# MLB0_MLBDIM_WRAP_ECC_AGGR_VBP register map
Vendor: Texas Instruments
Peripheral module from a debugger description file (folder J7ES).
Registers are 32-bit, access not given, reset 0x0 unless marked. A register's access mark holds for its fields unless they carry their own. Offsets are as the file gives them; lines under a group give offsets from that group; [hi:lo] are bit positions; {n}, {i} and the like mark numbered series; 'fields as' and 'values as' point back to an identical list; <NAME> marks a mode.

## MLB0_MLBDIM_WRAP_ECC_AGGR_VBP
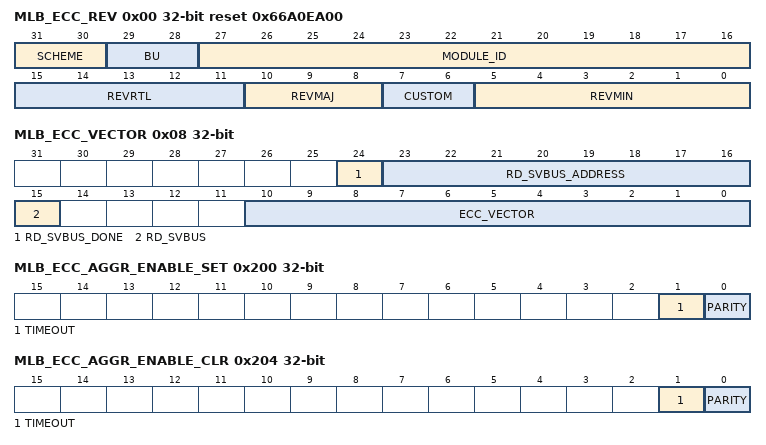
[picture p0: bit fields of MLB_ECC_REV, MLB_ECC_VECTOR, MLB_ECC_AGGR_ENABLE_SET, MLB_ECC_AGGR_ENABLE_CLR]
0x00 MLB_ECC_REV ro reset 0x66A0EA00 — Revision parameters
  [31:30] SCHEME
  [29:28] BU
  [27:16] MODULE_ID
  [15:11] REVRTL — RTL version
  [10:8] REVMAJ — Major version
  [7:6] CUSTOM — Custom version
  [5:0] REVMIN — Minor version
0x08 MLB_ECC_VECTOR — ECC Vector Register
  [24] RD_SVBUS_DONE — Status to indicate if read on serial VBUS is complete, write of any value will clear this bit. (access RW1C)
  [23:16] RD_SVBUS_ADDRESS rw — Read address
  [15] RD_SVBUS — Write 1 to trigger a read on the serial VBUS (access RW1S)
  [10:0] ECC_VECTOR rw — Value written to select the corresponding ECC RAM for control or status
0x0C MLB_ECC_STAT ro reset 0x1 — Misc Status
  [10:0] NUM_RAMS — Indicates the number of RAMS serviced by the ECC aggregator
0x10 MLB_ECC_RESERVED_SVBUS_y rw — Reference other documents that contain the ECC RAM wrapper and EDC controller serial vbus register sets. Offset = 10h + (y * 4h); where y = 0h to 7h
  [31:0] DATA — Serial VBUS register data
0x3C MLB_ECC_SEC_EOI_REG — EOI Register
  [0] EOI_WR — EOI Register (access RW1S)
0x40 MLB_ECC_SEC_STATUS_REG0 — Interrupt Status Register 0
  [0] DBMEM_PEND — Interrupt Pending Status for dbmem_pend (access RW1S)
0x80 MLB_ECC_SEC_ENABLE_SET_REG0 — Interrupt Enable Set Register 0
  [0] DBMEM_ENABLE_SET — Interrupt Enable Set Register for dbmem_pend (access RW1S)
0xC0 MLB_ECC_SEC_ENABLE_CLR_REG0 — Interrupt Enable Clear Register 0
  [0] DBMEM_ENABLE_CLR — Interrupt Enable Clear Register for dbmem_pend (access RW1C)
0x13C MLB_ECC_DED_EOI_REG — EOI Register
  [0] EOI_WR — EOI Register (access RW1S)
0x140 MLB_ECC_DED_STATUS_REG0 — Interrupt Status Register 0
  fields as MLB_ECC_SEC_STATUS_REG0
0x180 MLB_ECC_DED_ENABLE_SET_REG0 — Interrupt Enable Set Register 0
  fields as MLB_ECC_SEC_ENABLE_SET_REG0
0x1C0 MLB_ECC_DED_ENABLE_CLR_REG0 — Interrupt Enable Clear Register 0
  fields as MLB_ECC_SEC_ENABLE_CLR_REG0
0x200 MLB_ECC_AGGR_ENABLE_SET — AGGR interrupt enable set Register
  [1] TIMEOUT — interrupt enable set for svbus timeout errors (access RW1S)
  [0] PARITY — interrupt enable set for parity errors (access RW1S)
0x204 MLB_ECC_AGGR_ENABLE_CLR — AGGR interrupt enable clear Register
  [1] TIMEOUT — interrupt enable clear for svbus timeout errors (access RW1C)
  [0] PARITY — interrupt enable clear for parity errors (access RW1C)
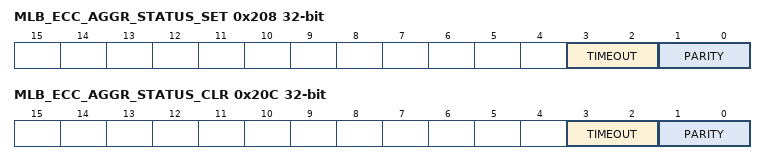
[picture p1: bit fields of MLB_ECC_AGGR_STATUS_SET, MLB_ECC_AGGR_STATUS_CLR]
0x208 MLB_ECC_AGGR_STATUS_SET — AGGR interrupt status set Register
  [3:2] TIMEOUT — interrupt status set for svbus timeout errors (access RWincr)
  [1:0] PARITY — interrupt status set for parity errors (access RWincr)
0x20C MLB_ECC_AGGR_STATUS_CLR — AGGR interrupt status clear Register
  [3:2] TIMEOUT — interrupt status clear for svbus timeout errors (access RWdecr)
  [1:0] PARITY — interrupt status clear for parity errors (access RWdecr)
